AUTOSAR XML (schema 4-2-2)
package /UAES/ASW
  swc implementation Implementation: programming-language=C, sw-version=5.3.1, used-code-generator=Embedded Coder 7.5 (R2020b) 29-Jul-2020, vendor-id=0, behavior=InternalBehavior
    code-descriptors:
      code Code
        artifact-descriptors:
          short-label=PwrModMngt_Ctrl_c, category=SWSRC
          short-label=PwrModMngt_Ctrl_h, category=SWHDR
          short-label=rtwtypes_h, category=SWHDR
    resource consumption RsrcCons_PwrModMngt_Ctrl
package /UAES/ASW/SwComponentTypes
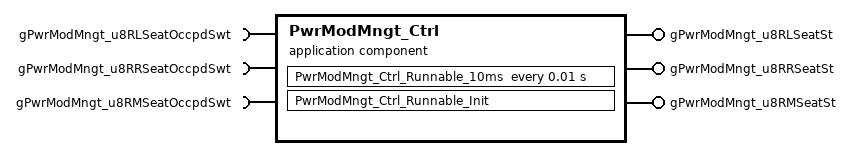
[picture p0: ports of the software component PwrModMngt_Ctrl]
  application sw component type PwrModMngt_Ctrl
    require port gPwrModMngt_u8RLSeatOccpdSwt: nonqueued-receiver-com-spec{data-element=gPwrModMngt_u8RLSeatOccpdSwt/Val, init-value=0}, required-interface=gPwrModMngt_u8RLSeatOccpdSwt
    require port gPwrModMngt_u8RRSeatOccpdSwt: nonqueued-receiver-com-spec{data-element=gPwrModMngt_u8RRSeatOccpdSwt/Val, init-value=0}, required-interface=gPwrModMngt_u8RRSeatOccpdSwt
    require port gPwrModMngt_u8RMSeatOccpdSwt: nonqueued-receiver-com-spec{data-element=gPwrModMngt_u8RMSeatOccpdSwt/Val, init-value=0}, required-interface=gPwrModMngt_u8RMSeatOccpdSwt
    provide port gPwrModMngt_u8RLSeatSt: nonqueued-sender-com-spec{data-element=gPwrModMngt_u8RLSeatSt/Val, init-value=0}, provided-interface=gPwrModMngt_u8RLSeatSt
    provide port gPwrModMngt_u8RRSeatSt: nonqueued-sender-com-spec{data-element=gPwrModMngt_u8RRSeatSt/Val, init-value=0}, provided-interface=gPwrModMngt_u8RRSeatSt
    provide port gPwrModMngt_u8RMSeatSt: nonqueued-sender-com-spec{data-element=gPwrModMngt_u8RMSeatSt/Val, init-value=0}, provided-interface=gPwrModMngt_u8RMSeatSt
    behavior InternalBehavior: handle-termination-and-restart=NO-SUPPORT
      init event PwrModMngt_Ctrl_InitEvent: start-on-event=PwrModMngt_Ctrl_Runnable_Init
      timing event TMT_PwrModMngt_Ctrl_Runnable_10ms: start-on-event=PwrModMngt_Ctrl_Runnable_10ms, period=0.01
      runnable PwrModMngt_Ctrl_Runnable_Init
        data-send-points:
          access OUT_gPwrModMngt_u8RLSeatSt_Val: accessed-variable=gPwrModMngt_u8RLSeatSt.Val
          access OUT_gPwrModMngt_u8RRSeatSt_Val: accessed-variable=gPwrModMngt_u8RRSeatSt.Val
          access OUT_gPwrModMngt_u8RMSeatSt_Val: accessed-variable=gPwrModMngt_u8RMSeatSt.Val
      runnable PwrModMngt_Ctrl_Runnable_10ms
        data-receive-point-by-arguments:
          access IN_gPwrModMngt_u8RLSeatOccpdSwt_Val: accessed-variable=gPwrModMngt_u8RLSeatOccpdSwt.Val
          access IN_gPwrModMngt_u8RMSeatOccpdSwt_Val: accessed-variable=gPwrModMngt_u8RMSeatOccpdSwt.Val
          access IN_gPwrModMngt_u8RRSeatOccpdSwt_Val: accessed-variable=gPwrModMngt_u8RRSeatOccpdSwt.Val
        data-send-points:
          access OUT_gPwrModMngt_u8RLSeatSt_Val: accessed-variable=gPwrModMngt_u8RLSeatSt.Val
          access OUT_gPwrModMngt_u8RRSeatSt_Val: accessed-variable=gPwrModMngt_u8RRSeatSt.Val
          access OUT_gPwrModMngt_u8RMSeatSt_Val: accessed-variable=gPwrModMngt_u8RMSeatSt.Val
package /UAES/ASW/PortInterfaces
  6 x sender receiver interface:
    gPwrModMngt_u8RLSeatOccpdSwt
      data Val: category=VALUE, sw-calibration-access=READ-ONLY, type=uint8
    gPwrModMngt_u8RRSeatOccpdSwt
      data Val: category=VALUE, sw-calibration-access=READ-ONLY, type=uint8
    gPwrModMngt_u8RMSeatOccpdSwt
      data Val: category=VALUE, sw-calibration-access=READ-ONLY, type=uint8
    gPwrModMngt_u8RLSeatSt
      data Val: category=VALUE, sw-calibration-access=READ-ONLY, type=uint8
    gPwrModMngt_u8RRSeatSt
      data Val: category=VALUE, sw-calibration-access=READ-ONLY, type=uint8
    gPwrModMngt_u8RMSeatSt
      data Val: category=VALUE, sw-calibration-access=READ-ONLY, type=uint8
